# TMS320F280049 register map
Vendor: Texas Instruments; Series: C2000 F28004x; File version: 0.2.0-generated
Registers are 16-bit, read-write, reset 0x0 unless marked. A register's access mark holds for its fields unless they carry their own. Offsets are from the block's base; [hi:lo] are bit positions; {n}, {i} and the like mark numbered series.

## CPUSYSREGS — CPU SYS Registers
Base 0x000BA600
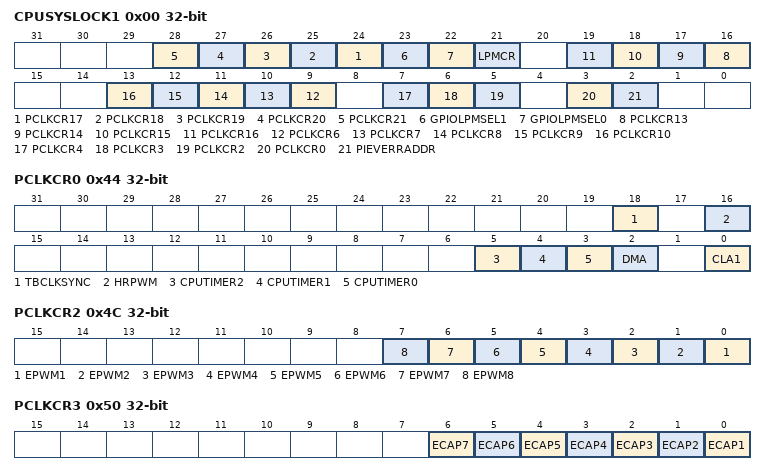
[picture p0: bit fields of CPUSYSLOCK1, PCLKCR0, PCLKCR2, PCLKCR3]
0x00 CPUSYSLOCK1 32-bit — Lock bit for CPUSYS registers
  [n+7] PCLKCR{n} (n=17..21) — Lock bit for PCLKCR{n} Register
  [23] GPIOLPMSEL1 — Lock bit for GPIOLPMSEL1 Register
  [22] GPIOLPMSEL0 — Lock bit for GPIOLPMSEL0 Register
  [21] LPMCR — Lock bit for LPMCR Register
  [n+3] PCLKCR{n} (n=13..16) — Lock bit for PCLKCR{n} Register
  [n+3] PCLKCR{n} (n=6..10) — Lock bit for PCLKCR{n} Register
  [7] PCLKCR4 — Lock bit for PCLKCR4 Register
  [6] PCLKCR3 — Lock bit for PCLKCR3 Register
  [5] PCLKCR2 — Lock bit for PCLKCR2 Register
  [3] PCLKCR0 — Lock bit for PCLKCR0 Register
  [2] PIEVERRADDR — Lock bit for PIEVERRADDR Register
0x14 PIEVERRADDR 32-bit — PIE Vector Fetch Error Address register
  [31:21] ADDR — PIE Vector Fetch Error Handler Routine Address
0x44 PCLKCR0 32-bit — Peripheral Clock Gating Registers
  [18] TBCLKSYNC — EPWM Time Base Clock sync
  [16] HRPWM — HRPWM Clock Enable Bit
  [5] CPUTIMER2 — CPUTIMER2 Clock Enable bit
  [4] CPUTIMER1 — CPUTIMER1 Clock Enable bit
  [3] CPUTIMER0 — CPUTIMER0 Clock Enable bit
  [2] DMA — DMA Clock Enable bit
  [0] CLA1 — CLA1 Clock Enable Bit
0x4C PCLKCR2 32-bit — Peripheral Clock Gating Registers
  [n-1] EPWM{n} (n=1..8) — EPWM{n} Clock Enable bit
0x50 PCLKCR3 32-bit — Peripheral Clock Gating Registers
  [n-1] ECAP{n} (n=1..7) — ECAP{n} Clock Enable bit
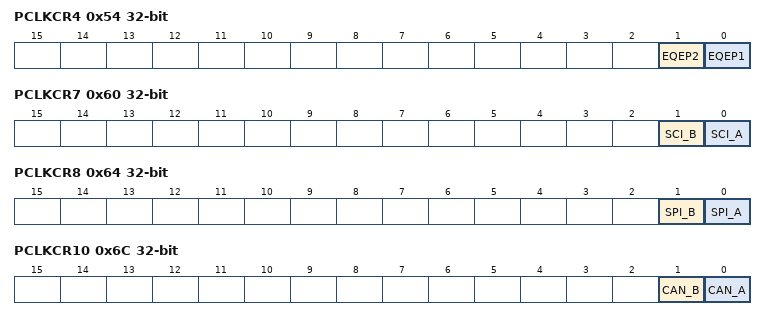
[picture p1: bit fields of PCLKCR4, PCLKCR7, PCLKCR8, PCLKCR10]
0x54 PCLKCR4 32-bit — Peripheral Clock Gating Registers
  [1] EQEP2 — EQEP2 Clock Enable bit
  [0] EQEP1 — EQEP1 Clock Enable bit
0x5C PCLKCR6 32-bit — Peripheral Clock Gating Registers
  [0] SD1 — SD1 Clock Enable bit
0x60 PCLKCR7 32-bit — Peripheral Clock Gating Registers
  [1] SCI_B — SCI_B Clock Enable bit
  [0] SCI_A — SCI_A Clock Enable bit
0x64 PCLKCR8 32-bit — Peripheral Clock Gating Registers
  [1] SPI_B — SPI_B Clock Enable bit
  [0] SPI_A — SPI_A Clock Enable bit
0x68 PCLKCR9 32-bit — Peripheral Clock Gating Registers
  [0] I2C_A — I2C_A Clock Enable bit
0x6C PCLKCR10 32-bit — Peripheral Clock Gating Registers
  [1] CAN_B — CAN_B Clock Enable bit
  [0] CAN_A — CAN_A Clock Enable bit
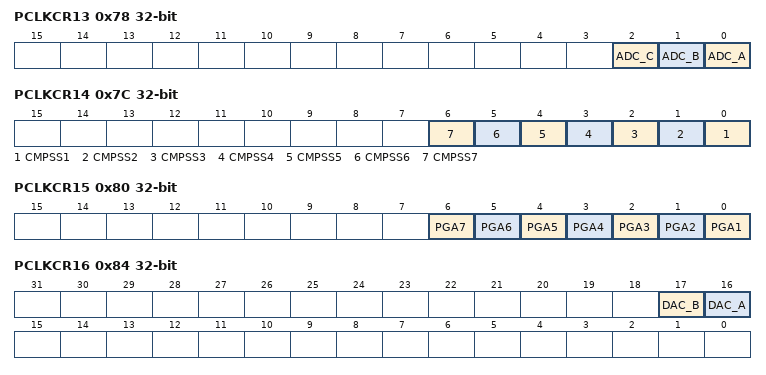
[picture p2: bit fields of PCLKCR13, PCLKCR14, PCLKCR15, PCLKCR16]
0x78 PCLKCR13 32-bit — Peripheral Clock Gating Registers
  [2] ADC_C — ADC_C Clock Enable bit
  [1] ADC_B — ADC_B Clock Enable bit
  [0] ADC_A — ADC_A Clock Enable bit
0x7C PCLKCR14 32-bit — Peripheral Clock Gating Registers
  [n-1] CMPSS{n} (n=1..7) — CMPSS{n} Clock Enable bit
0x80 PCLKCR15 32-bit — Peripheral Clock Gating Registers
  [n-1] PGA{n} (n=1..7) — PGA{n} Clock Enable bit
0x84 PCLKCR16 32-bit — Peripheral Clock Gating Registers
  [17] DAC_B — Buffered_DAC_B Clock Enable Bit
  [16] DAC_A — Buffered_DAC_A Clock Enable Bit
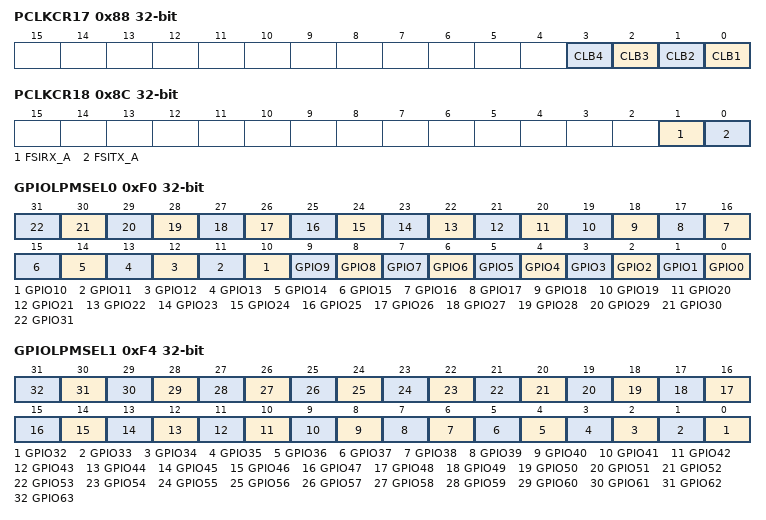
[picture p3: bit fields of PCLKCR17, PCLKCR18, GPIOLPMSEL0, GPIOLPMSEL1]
0x88 PCLKCR17 32-bit — Peripheral Clock Gating Registers
  [n-1] CLB{n} (n=1..4) — CLB{n} Clock Enable bit
0x8C PCLKCR18 32-bit — Peripheral Clock Gating Registers
  [1] FSIRX_A — FSIRX_A Clock Enable bit
  [0] FSITX_A — FSITX_A Clock Enable bit
0x90 PCLKCR19 32-bit — Peripheral Clock Gating Registers
  [0] LIN_A — LIN_A Clock Enable bit
0x94 PCLKCR20 32-bit — Peripheral Clock Gating Registers
  [0] PMBUS_A — PMBUS_A Clock Enable bit
0x98 PCLKCR21 32-bit — Peripheral Clock Gating Registers
  [0] DCC_0 — DCC_0 Clock Enable Bit
0xEC LPMCR 32-bit — LPM Control Register
  [2:1] LPM — Low Power Mode setting
0xF0 GPIOLPMSEL0 32-bit — GPIO LPM Wakeup select registers
  [n] GPIO{n} (n=0..31) — GPIO{n} Enable for LPM Wakeup
0xF4 GPIOLPMSEL1 32-bit — GPIO LPM Wakeup select registers
  [n-32] GPIO{n} (n=32..63) — GPIO{n} Enable for LPM Wakeup
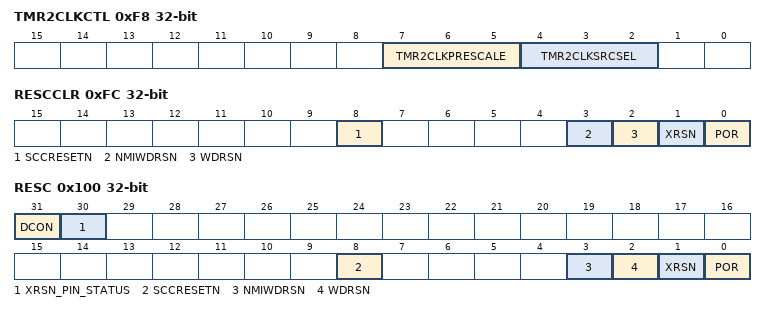
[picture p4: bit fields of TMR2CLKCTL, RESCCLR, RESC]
0xF8 TMR2CLKCTL 32-bit — Timer2 Clock Measurement functionality control register
  [7:5] TMR2CLKPRESCALE — CPU Timer 2 Clock Pre-Scale Value
  [4:2] TMR2CLKSRCSEL — CPU Timer 2 Clock Source Select Bit
0xFC RESCCLR 32-bit — Reset Cause Clear Register
  [8] SCCRESETN — SCCRESETn Reset Cause Indication Bit
  [3] NMIWDRSN — NMIWDRSn Reset Cause Indication Bit
  [2] WDRSN — WDRSn Reset Cause Indication Bit
  [1] XRSN — XRSn Reset Cause Indication Bit
  [0] POR — POR Reset Cause Indication Bit
0x100 RESC 32-bit — Reset Cause register
  [31] DCON — Debugger conntion status to C28x
  [30] XRSN_PIN_STATUS
  [8] SCCRESETN — SCCRESETn Reset Cause Indication Bit
  [3] NMIWDRSN — NMIWDRSn Reset Cause Indication Bit
  [2] WDRSN — WDRSn Reset Cause Indication Bit
  [1] XRSN — XRSn Reset Cause Indication Bit
  [0] POR — POR Reset Cause Indication Bit
